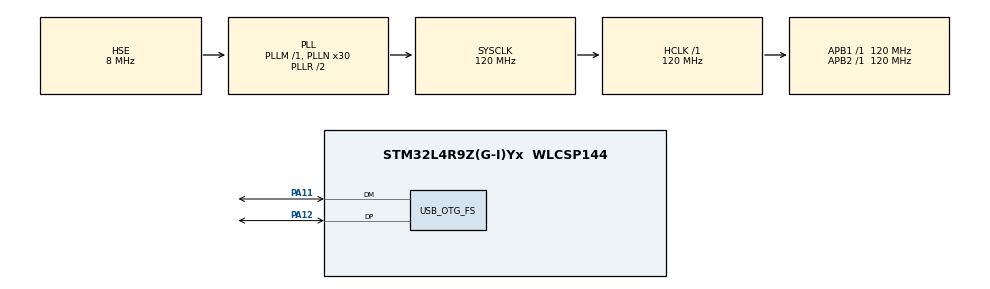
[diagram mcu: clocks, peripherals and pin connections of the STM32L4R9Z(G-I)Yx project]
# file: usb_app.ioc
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Mcu.Family=STM32L4
Mcu.Name=STM32L4R9Z(G-I)Yx
Mcu.Package=WLCSP144
NVIC.OTG_FS_IRQn=true\:0\:0\:false\:false\:true\:false\:true\:true
NVIC.PriorityGroup=NVIC_PRIORITYGROUP_4
PA11.Mode=Device_Only
PA11.Signal=USB_OTG_FS_DM
PA12.Mode=Device_Only
PA12.Signal=USB_OTG_FS_DP
PH0-OSC_IN\ (PH0).Mode=HSE-External-Oscillator
PH0-OSC_IN\ (PH0).Signal=RCC_OSC_IN
PH1-OSC_OUT\ (PH1).Mode=HSE-External-Oscillator
PH1-OSC_OUT\ (PH1).Signal=RCC_OSC_OUT
ProjectManager.HeapSize=0x200
ProjectManager.StackSize=0x400
ProjectManager.TargetToolchain=STM32CubeIDE
RCC.ADCFreq_Value=96000000
RCC.AHBFreq_Value=120000000
RCC.APB1Freq_Value=120000000
RCC.APB1TimFreq_Value=120000000
RCC.APB2Freq_Value=120000000
RCC.APB2TimFreq_Value=120000000
RCC.CK48CLockSelection=RCC_USBCLKSOURCE_HSI48
RCC.CortexFreq_Value=120000000
RCC.HCLKFreq_Value=120000000
RCC.HSE_VALUE=8000000
RCC.HSI48_VALUE=48000000
RCC.HSI_VALUE=16000000
RCC.LSE_VALUE=32768
RCC.MSIAutoCalibration=ENABLED
RCC.MSI_VALUE=4000000
RCC.PLLN=30
RCC.PLLSAI1N=24
RCC.PLLSourceVirtual=RCC_PLLSOURCE_HSE
RCC.SYSCLKFreq_VALUE=120000000
RCC.SYSCLKSource=RCC_SYSCLKSOURCE_PLLCLK
RCC.USBFreq_Value=48000000
RCC.VCOOutputFreq_Value=240000000
USB_DEVICE.CLASS_NAME_FS=CDC
USB_DEVICE.PRODUCT_STRING_CDC_FS=liqxtal Virtual ComPort
USB_DEVICE.VirtualMode=Cdc
USB_DEVICE.VirtualModeFS=Cdc_FS
USB_OTG_FS.VirtualMode=Device_Only
VP_USB_DEVICE_VS_USB_DEVICE_CDC_FS.Mode=CDC_FS
board=custom

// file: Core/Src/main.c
/* USER CODE BEGIN Header */
/**
  ******************************************************************************
  * @file           : main.c
  * @brief          : Main program body
  ******************************************************************************
  * @attention
  *
  * Copyright (c) 2025 STMicroelectronics.
  * All rights reserved.
  *
  * This software is licensed under terms that can be found in the LICENSE file
  * in the root directory of this software component.
  * If no LICENSE file comes with this software, it is provided AS-IS.
  *
  ******************************************************************************
  */
/* USER CODE END Header */
#include "main.h"
#include "usb_device.h"
#include "Flash.h"

/* USER CODE BEGIN PD */
#define MEMORY_512KB
const uint8_t firmware=250202;
const char firmware1[]="250203";
volatile const char firmware2[]="FW250204";

/* USER CODE END PD */

void SystemClock_Config(void);
static void MX_GPIO_Init(void);
/* USER CODE BEGIN PFP */
//#define VERINFO_ADDR_BASE (0x08008040)
//const char Firmware_Ver[] __attriute__(at(VERINFO_ADDR_BASE +0x40)) = "Firmware: 1.0.0";

const char Firmware_Ver[] __attribute__((section(".firmware_version"))) = "FW: 25.2.1";

/* USER CODE END PFP */

/* USER CODE BEGIN 0 */
//typedef struct __attribute__((packed)){
//    uint16_t image_magic;
//    uint16_t image_version;
//    uint32_t image_size;
//    uint32_t crc;
//
//} image_hdr_t;

//image_hdr_t image_hdr __attribute__((section(".fw_header")))= {
//    .image_magic = 0,
//    .image_version = 250204,
//    .image_size = 0,               //to be added manually using crc.py script after build
//    .crc = 0                       //-do-
//};

/* USER CODE END 0 */

int main(void)
{
  /* USER CODE BEGIN 1 */
	  /*
	   * App1
	   * change the flash size and flash origin in FLASH.ld file like:
	   * FLASH    (rx)    : ORIGIN = 0x8008000,   LENGTH = 22K //64K
	   *
	   * in system_stm32f1xx.c change VECT_TAB_OFFSET to your new value like 0x00008000U
	   * #define USER_VECT_TAB_ADDRESS //First uncomment this in system_stm32f1xx.c
	   * #define VECT_TAB_OFFSET         0x00008000U
	   */
  /* USER CODE END 1 */

  /* MCU Configuration--------------------------------------------------------*/

  /* Reset of all peripherals, Initializes the Flash interface and the Systick. */
  HAL_Init();

  /* Configure the system clock */
  SystemClock_Config();

  /* Initialize all configured peripherals */
  MX_GPIO_Init();
  MX_USB_DEVICE_Init();
  /* USER CODE BEGIN 2 */

  uint32_t pageAddress = ADDR_FLASH_PAGE_63; // Replace with your target page address
  uint32_t flashAddress = 0x0801F800; // Replace with your target flash address
  uint64_t data = 0x12345678; // Data to write (64-bit)

  HAL_StatusTypeDef status = FlashErase(pageAddress);
  status = FlashWrite(flashAddress, data);
  uint64_t readdata = FlashRead(flashAddress);
  flashAddress = 8;
  uint64_t readdata2 = FlashRead(flashAddress);

  /* USER CODE END 2 */

  /* Infinite loop */
  while (1)
  {

  }
}

void SystemClock_Config(void)
{
  RCC_OscInitTypeDef RCC_OscInitStruct = {0};
  RCC_ClkInitTypeDef RCC_ClkInitStruct = {0};

  /** Configure the main internal regulator output voltage
  */
  if (HAL_PWREx_ControlVoltageScaling(PWR_REGULATOR_VOLTAGE_SCALE1_BOOST) != HAL_OK)
  {
    Error_Handler();
  }

  /** Initializes the RCC Oscillators according to the specified parameters
  * in the RCC_OscInitTypeDef structure.
  */
  RCC_OscInitStruct.OscillatorType = RCC_OSCILLATORTYPE_HSI48|RCC_OSCILLATORTYPE_HSE;
  RCC_OscInitStruct.HSEState = RCC_HSE_ON;
  RCC_OscInitStruct.HSI48State = RCC_HSI48_ON;
  RCC_OscInitStruct.PLL.PLLState = RCC_PLL_ON;
  RCC_OscInitStruct.PLL.PLLSource = RCC_PLLSOURCE_HSE;
  RCC_OscInitStruct.PLL.PLLM = 1;
  RCC_OscInitStruct.PLL.PLLN = 30;
  RCC_OscInitStruct.PLL.PLLP = RCC_PLLP_DIV2;
  RCC_OscInitStruct.PLL.PLLQ = RCC_PLLQ_DIV2;
  RCC_OscInitStruct.PLL.PLLR = RCC_PLLR_DIV2;
  if (HAL_RCC_OscConfig(&RCC_OscInitStruct) != HAL_OK)
  {
    Error_Handler();
  }

  /** Initializes the CPU, AHB and APB buses clocks
  */
  RCC_ClkInitStruct.ClockType = RCC_CLOCKTYPE_HCLK|RCC_CLOCKTYPE_SYSCLK
                              |RCC_CLOCKTYPE_PCLK1|RCC_CLOCKTYPE_PCLK2;
  RCC_ClkInitStruct.SYSCLKSource = RCC_SYSCLKSOURCE_PLLCLK;
  RCC_ClkInitStruct.AHBCLKDivider = RCC_SYSCLK_DIV1;
  RCC_ClkInitStruct.APB1CLKDivider = RCC_HCLK_DIV1;
  RCC_ClkInitStruct.APB2CLKDivider = RCC_HCLK_DIV1;

  if (HAL_RCC_ClockConfig(&RCC_ClkInitStruct, FLASH_LATENCY_5) != HAL_OK)
  {
    Error_Handler();
  }

  /** Enable MSI Auto calibration
  */
  HAL_RCCEx_EnableMSIPLLMode();
}

static void MX_GPIO_Init(void)
{

  /* GPIO Ports Clock Enable */
  __HAL_RCC_GPIOA_CLK_ENABLE();
  __HAL_RCC_GPIOH_CLK_ENABLE();

}

/* USER CODE BEGIN 4 */

void USB_CDC_RxHandler(uint8_t* USB_Buf, uint32_t Len)
{
	USB_Buf[0]=USB_Buf[0];
	//CDC_Transmit_FS((uint8_t*)"FW:250204", sizeof("FW:250204") - 1);
}
/* USER CODE END 4 */

void Error_Handler(void)
{
  __disable_irq();
  while (1)
  {
  }
}
